AUTOSAR XML (schema 00049)
standard types defined: boolean, float32, sint16, uint16, uint8, boolean_CompuMethod, boolean_DataConstr, float32_DataConstr, uint16_DataConstr, uint8_DataConstr
package /AUTOSAR_Platform/ImplementationDataTypes
  impl type sint16_const: category=VALUE, base-type=sint16, range raw -32768..32767, additional-native-type-qualifier=const  # SInt16 represents integers with a minimum value of -32768 and a maximum value of 32767. The order-relation on sint16 is: x < y if y - x is positive. sint16 has a lexical representation consisting of an optional sign followed by a finite-length sequence of decimal digits (#x30-#x39). If the sign is omitted, "+" is assumed. For example: -1, 0, -12678, +10000, 2500
package /ComponentTypes
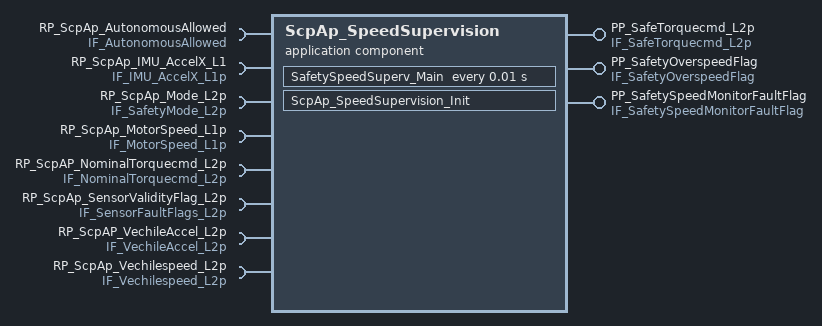
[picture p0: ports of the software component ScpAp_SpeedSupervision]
  application sw component type ScpAp_SpeedSupervision
    8 x require port:
      RP_ScpAp_AutonomousAllowed: nonqueued-receiver-com-spec{data-element=IF_AutonomousAllowed, init-value=0}, required-interface=IF_AutonomousAllowed
      RP_ScpAp_IMU_AccelX_L1: nonqueued-receiver-com-spec{data-element=IF_IMU_AccelX_L1p, init-value=0}, required-interface=IF_IMU_AccelX_L1p
      RP_ScpAp_Mode_L2p: nonqueued-receiver-com-spec{data-element=IF_SafetyMode_L2p, init-value=AUTONOMOUS}, required-interface=IF_SafetyMode_L2p
      RP_ScpAp_MotorSpeed_L1p: nonqueued-receiver-com-spec{data-element=IF_MotorSpeed_L1p, init-value=0}, required-interface=IF_MotorSpeed_L1p
      RP_ScpAP_NominalTorquecmd_L2p: nonqueued-receiver-com-spec{data-element=IF_NominalTorquecmd_L2p, init-value=0}, required-interface=IF_NominalTorquecmd_L2p
      RP_ScpAp_SensorValidityFlag_L2p: nonqueued-receiver-com-spec{data-element=IF_SensorFaultFlags_L2p, init-value={short-label=ComSpec1fa9c3ec_c3d8f77079db14a8, fields=[MotorRPM_Fault:0, Accel_Fault:0, WSS_Fault:0, VechSpeedEst_Fault:0]}}, required-interface=IF_SensorFaultFlags_L2p
      RP_ScpAP_VechileAccel_L2p: nonqueued-receiver-com-spec{data-element=IF_VechileAccel_L2p, init-value=ComSpec0c8c5ef8_4a6076e13953ca91:0}, required-interface=IF_VechileAccel_L2p
      RP_ScpAp_Vechilespeed_L2p: nonqueued-receiver-com-spec{data-element=IF_Vechilespeed_L2p, init-value=ComSpecdd0fd142_431cf985fad10dc1:0}, required-interface=IF_Vechilespeed_L2p
    provide port PP_SafeTorquecmd_L2p: nonqueued-sender-com-spec{data-element=IF_SafeTorquecmd_L2p, init-value=ComSpec4be8d265_1f78bf7bf99dd5fa:0}, provided-interface=IF_SafeTorquecmd_L2p
    provide port PP_SafetyOverspeedFlag: nonqueued-sender-com-spec{data-element=IF_SafetyOverspeedFlag, init-value=0}, provided-interface=IF_SafetyOverspeedFlag
    provide port PP_SafetySpeedMonitorFaultFlag: nonqueued-sender-com-spec{data-element=IF_SafetySpeedMonitorFaultFlag, init-value=0}, provided-interface=IF_SafetySpeedMonitorFaultFlag
    behavior ScpAp_SpeedSupervision_InternalBehavior: handle-termination-and-restart=NO-SUPPORT
      constant-memorys:
        8 x parameter data prototype, all with category=VALUE, sw-addr-method=CALIB, sw-calibration-access=READ-WRITE:
          K_Pred: type=float64_const, init-value=K_Pred:0.003
          TH_Hystersis: type=float64_const, init-value=TH_Hystersis:3
          TH_Mon_Accel_Diff: type=float64_const, init-value=TH_Mon_Accel_Diff:2
          TH_Mon_Speed_Diff: type=float64_const, init-value=TH_Mon_Speed_Diff:2
          TH_Pred_Margin: type=float64_const, init-value=TH_Pred_Margin:2
          TH_Speed_Limit_Margin: type=float64_const, init-value=TH_Speed_Limit_Margin:3
          Torque_Decel_Limit: type=sint16_const, init-value=Torque_Decel_Limit:500
          Torque_PreLimit: type=sint16_const, init-value=Torque_PreLimit:600
      static-memorys:
        18 x data, all with category=VALUE, sw-addr-method=ASW_Variables, sw-calibration-access=READ-ONLY:
          SpeedMonitorFaultFlag: type=boolean
          OverSpeedFlg_Raw: type=boolean
          ScpAp_S_SpeedMonitorFaultFlag_1: type=float64
          ScpAp_SpeedSupe_Predicted_Speed: type=float64
          ScpAp_Spee_OverspeedPredictFlag: type=float64
          ScpAp_S_SpeedMonitorFault_Flg_3: type=float64
          ScpAp_SpeedS_OverSpeedFlg_Raw_2: type=float64
          ScpAp_S_SpeedMonitorFault_Flg_2: type=float64
          ScpAp_Spee_OvrSpdPredictFlg_Chk: type=sint16
          ScpAp_SpeedSuper_OverSpdFlg_Chk: type=sint16
          ScpAp_SpeedSup_SafeTorqueCmd_L2: type=sint16
          ScpAp_SpeedSupervisi_Autonomous: type=boolean
          ScpAp_Spe_SpeedMonitorFaultFlag: type=boolean
          ScpAp_SpeedSup_OverSpeedFlg_Raw: type=boolean
          ScpAp_NominalTrq_Equal_SafeTrq: type=boolean
          ScpAp_SpeedS_OverSpeedFlg_Raw_1: type=boolean
          ScpAp_Spe_OverspeedFlag_Latched: type=boolean
          ScpAp_SpeedSuperv_OverSpeed_Flg: type=boolean
      timing event TMT_SaeftySpeedSuperv_Main: start-on-event=SafetySpeedSuperv_Main, period=0.01
      runnable SafetySpeedSuperv_Main: sw-addr-method=CODE
        data-receive-point-by-arguments:
          8 x access:
            IN_RP_ScpAP_NominalTorquecmd_L2p_IF_NominalTorquecmd_L2p: accessed-variable=RP_ScpAP_NominalTorquecmd_L2p.IF_NominalTorquecmd_L2p
            IN_RP_ScpAP_VechileAccel_L2p_IF_VechileAccel_L2p: accessed-variable=RP_ScpAP_VechileAccel_L2p.IF_VechileAccel_L2p
            IN_RP_ScpAp_AutonomousAllowed_IF_AutonomousAllowed: accessed-variable=RP_ScpAp_AutonomousAllowed.IF_AutonomousAllowed
            IN_RP_ScpAp_IMU_AccelX_L1_IF_IMU_AccelX_L1p: accessed-variable=RP_ScpAp_IMU_AccelX_L1.IF_IMU_AccelX_L1p
            IN_RP_ScpAp_Mode_L2p_IF_SafetyMode_L2p: accessed-variable=RP_ScpAp_Mode_L2p.IF_SafetyMode_L2p
            IN_RP_ScpAp_MotorSpeed_L1p_IF_MotorSpeed_L1p: accessed-variable=RP_ScpAp_MotorSpeed_L1p.IF_MotorSpeed_L1p
            IN_RP_ScpAp_SensorValidityFlag_L2p_IF_SensorFaultFlags_L2p: accessed-variable=RP_ScpAp_SensorValidityFlag_L2p.IF_SensorFaultFlags_L2p
            IN_RP_ScpAp_Vechilespeed_L2p_IF_Vechilespeed_L2p: accessed-variable=RP_ScpAp_Vechilespeed_L2p.IF_Vechilespeed_L2p
        data-send-points:
          access OUT_PP_SafeTorquecmd_L2p_IF_SafeTorquecmd_L2p: accessed-variable=PP_SafeTorquecmd_L2p.IF_SafeTorquecmd_L2p
          access OUT_PP_SafetyOverspeedFlag_IF_SafetyOverspeedFlag: accessed-variable=PP_SafetyOverspeedFlag.IF_SafetyOverspeedFlag
          access OUT_PP_SafetySpeedMonitorFaultFlag_IF_SafetySpeedMonitorFaultFlag: accessed-variable=PP_SafetySpeedMonitorFaultFlag.IF_SafetySpeedMonitorFaultFlag
      runnable ScpAp_SpeedSupervision_Init: sw-addr-method=CODE
package /DataTypes
  impl type IF_SensorFaultFlgs_L2p_IDT: category=STRUCTURE
    4 x element, all with category=TYPE_REFERENCE, implementation-data-type=boolean:
      MotorRPM_Fault
      Accel_Fault
      WSS_Fault
      VechSpeedEst_Fault
  impl type SafetyMode_L2p_IDT: category=VALUE, base-type=BaseTypes/uint8, compu {1=AUTONOMOUS, 0=MANUAL, 3=TELEOPS}, data-constr=DC_SafetyMode_L2p_IDT
package /PortInterfaces
  11 x sender receiver interface:
    IF_AutonomousAllowed: invalidation-policy{data-element=IF_AutonomousAllowed, handle-invalid=DONT-INVALIDATE}
      data IF_AutonomousAllowed: category=VALUE, sw-calibration-access=READ-ONLY, type=boolean
    IF_IMU_AccelX_L1p: invalidation-policy{data-element=IF_IMU_AccelX_L1p, handle-invalid=DONT-INVALIDATE}
      data IF_IMU_AccelX_L1p: category=VALUE, sw-calibration-access=READ-ONLY, type=float32
    IF_MotorSpeed_L1p: invalidation-policy{data-element=IF_MotorSpeed_L1p, handle-invalid=DONT-INVALIDATE}
      data IF_MotorSpeed_L1p: category=VALUE, sw-calibration-access=READ-ONLY, type=uint8
    IF_NominalTorquecmd_L2p: invalidation-policy{data-element=IF_NominalTorquecmd_L2p, handle-invalid=DONT-INVALIDATE}
      data IF_NominalTorquecmd_L2p: category=VALUE, sw-calibration-access=READ-ONLY, type=sint16
    IF_SafeTorquecmd_L2p: invalidation-policy{data-element=IF_SafeTorquecmd_L2p, handle-invalid=DONT-INVALIDATE}
      data IF_SafeTorquecmd_L2p: category=VALUE, sw-calibration-access=READ-ONLY, type=sint16
    IF_SafetyMode_L2p: invalidation-policy{data-element=IF_SafetyMode_L2p, handle-invalid=DONT-INVALIDATE}
      data IF_SafetyMode_L2p: category=VALUE, sw-calibration-access=READ-ONLY, type=SafetyMode_L2p_IDT
    IF_SafetyOverspeedFlag: invalidation-policy{data-element=IF_SafetyOverspeedFlag, handle-invalid=DONT-INVALIDATE}
      data IF_SafetyOverspeedFlag: category=VALUE, sw-calibration-access=READ-ONLY, type=boolean
    IF_SafetySpeedMonitorFaultFlag: invalidation-policy{data-element=IF_SafetySpeedMonitorFaultFlag, handle-invalid=DONT-INVALIDATE}
      data IF_SafetySpeedMonitorFaultFlag: category=VALUE, sw-calibration-access=READ-ONLY, type=boolean
    IF_SensorFaultFlags_L2p: invalidation-policy{data-element=IF_SensorFaultFlags_L2p, handle-invalid=DONT-INVALIDATE}
      data IF_SensorFaultFlags_L2p: category=STRUCTURE, sw-calibration-access=READ-ONLY, type=IF_SensorFaultFlgs_L2p_IDT
    IF_VechileAccel_L2p: invalidation-policy{data-element=IF_VechileAccel_L2p, handle-invalid=DONT-INVALIDATE}
      data IF_VechileAccel_L2p: category=VALUE, sw-calibration-access=READ-ONLY, type=sint16
    IF_Vechilespeed_L2p: invalidation-policy{data-element=IF_Vechilespeed_L2p, handle-invalid=DONT-INVALIDATE}
      data IF_Vechilespeed_L2p: category=VALUE, sw-calibration-access=READ-ONLY, type=uint16
